VERSION "1.0"

NS_ :

BS_: 500000,1,10

BU_: ECU1 ECU2 ECU3

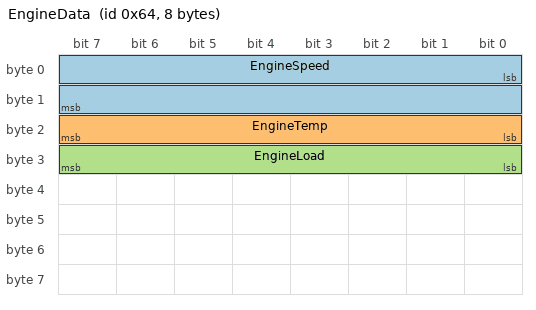
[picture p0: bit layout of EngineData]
BO_ 100 EngineData: 8 ECU1
 SG_ EngineSpeed : 0|16@1+ (0.1,0) [0|6500] "rpm" ECU2,ECU3
 SG_ EngineTemp : 16|8@1+ (1,-40) [-40|215] "degC" ECU2
 SG_ EngineLoad : 24|8@1+ (1,0) [0|100] "%" ECU2,ECU3

BO_ 200 TransmissionData: 6 ECU2
 SG_ GearPosition : 0|4@1+ (1,0) [0|8] "" ECU1,ECU3
 SG_ TransmissionMode M : 4|2@1+ (1,0) [0|3] "" ECU1,ECU3
 SG_ TransmissionTemp : 8|8@1+ (1,-40) [-40|215] "degC" ECU1
 SG_ TransmissionSpeed : 16|16@1+ (0.1,0) [0|6500] "rpm" ECU1,ECU3
 SG_ TransmissionInfo m0 : 32|8@1+ (1,0) [0|255] "" ECU1
 SG_ TransmissionPressure m1 : 32|8@1+ (1,0) [0|255] "kPa" ECU1

CM_ BU_ ECU1 "Engine Control Unit";
CM_ BU_ ECU2 "Transmission Control Unit";
CM_ BU_ ECU3 "Diagnostic Unit";
CM_ BO_ 100 "Engine data message";
CM_ SG_ 100 EngineSpeed "Engine speed in RPM";
CM_ SG_ 100 EngineTemp "Engine temperature in degrees Celsius";
CM_ SG_ 100 EngineLoad "Engine load as percentage";
CM_ BO_ 200 "Transmission data message";
CM_ SG_ 200 GearPosition "Current gear position";

BA_DEF_ BO_ "GenMsgCycleTime" INT 0 10000;
BA_DEF_DEF_ "GenMsgCycleTime" 100;
BA_ "GenMsgCycleTime" BO_ 200 200;

VAL_ 200 GearPosition 0 "Neutral" 1 "First" 2 "Second" 3 "Third" 4 "Fourth" 5 "Fifth" 6 "Sixth" 7 "Reverse" 8 "Park";
VAL_ 200 TransmissionMode 0 "Normal" 1 "Sport" 2 "Economy" 3 "Winter";
